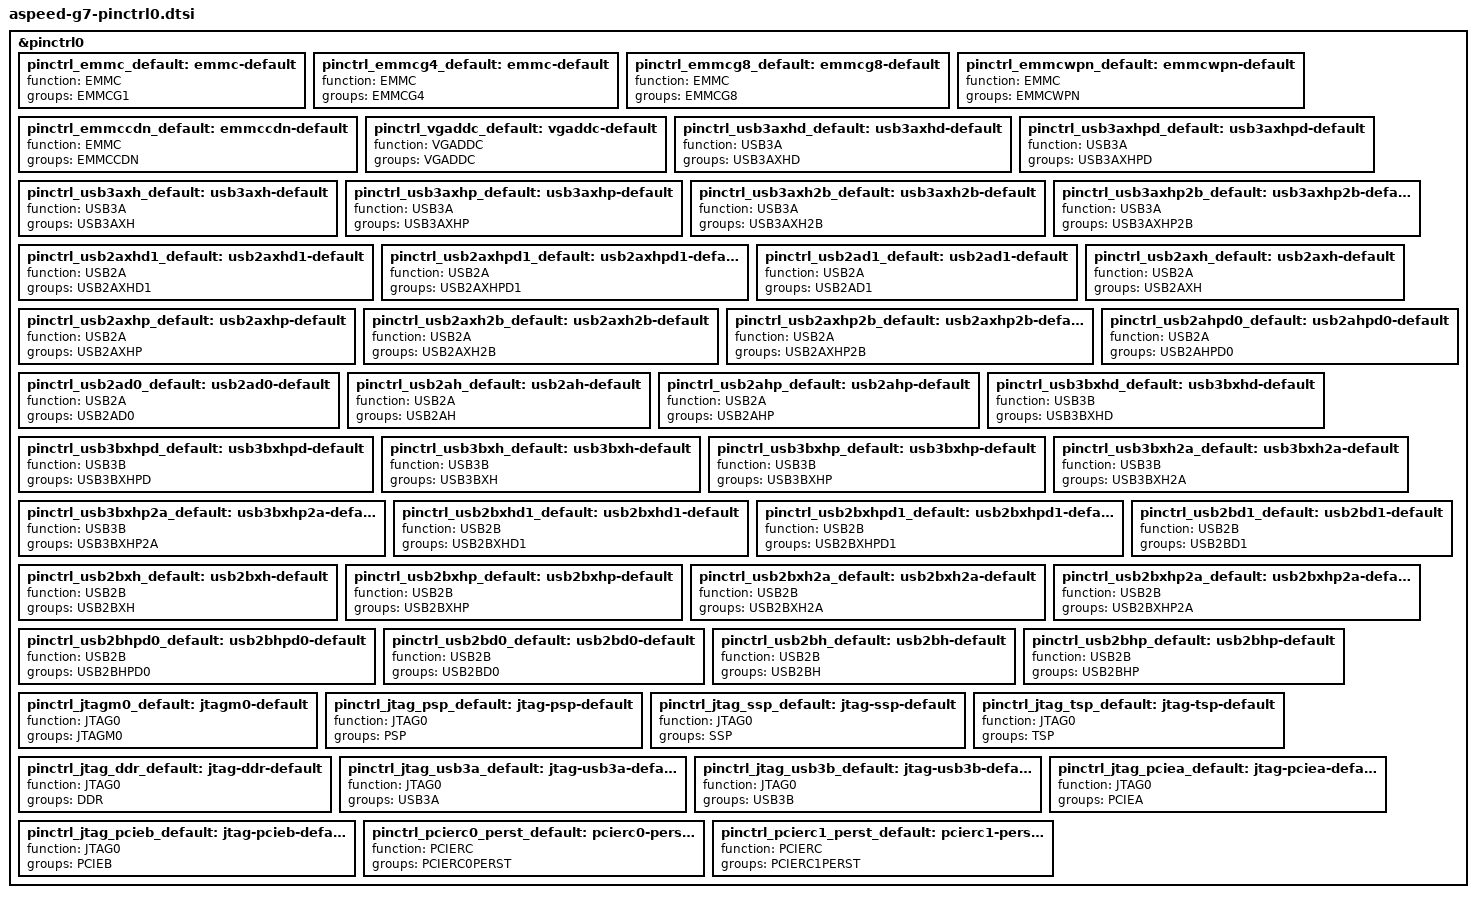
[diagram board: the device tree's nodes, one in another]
// SPDX-License-Identifier: GPL-2.0-or-later
// Copyright 2026 ASPEED Corp.

&pinctrl0 {
	pinctrl_emmc_default: emmc-default {
		function = "EMMC";
		groups = "EMMCG1";
	};

	pinctrl_emmcg4_default: emmc-default {
		function = "EMMC";
		groups = "EMMCG4";
	};

	pinctrl_emmcg8_default: emmcg8-default {
		function = "EMMC";
		groups = "EMMCG8";
	};

	pinctrl_emmcwpn_default: emmcwpn-default {
		function = "EMMC";
		groups = "EMMCWPN";
	};

	pinctrl_emmccdn_default: emmccdn-default {
		function = "EMMC";
		groups = "EMMCCDN";
	};

	pinctrl_vgaddc_default: vgaddc-default {
		function = "VGADDC";
		groups = "VGADDC";
	};

	pinctrl_usb3axhd_default: usb3axhd-default {
		function = "USB3A";
		groups = "USB3AXHD";
	};

	pinctrl_usb3axhpd_default: usb3axhpd-default {
		function = "USB3A";
		groups = "USB3AXHPD";
	};

	pinctrl_usb3axh_default: usb3axh-default {
		function = "USB3A";
		groups = "USB3AXH";
	};

	pinctrl_usb3axhp_default: usb3axhp-default {
		function = "USB3A";
		groups = "USB3AXHP";
	};

	pinctrl_usb3axh2b_default: usb3axh2b-default {
		function = "USB3A";
		groups = "USB3AXH2B";
	};

	pinctrl_usb3axhp2b_default: usb3axhp2b-default {
		function = "USB3A";
		groups = "USB3AXHP2B";
	};

	pinctrl_usb2axhd1_default: usb2axhd1-default {
		function = "USB2A";
		groups = "USB2AXHD1";
	};

	pinctrl_usb2axhpd1_default: usb2axhpd1-default {
		function = "USB2A";
		groups = "USB2AXHPD1";
	};

	pinctrl_usb2ad1_default: usb2ad1-default {
		function = "USB2A";
		groups = "USB2AD1";
	};

	pinctrl_usb2axh_default: usb2axh-default {
		function = "USB2A";
		groups = "USB2AXH";
	};

	pinctrl_usb2axhp_default: usb2axhp-default {
		function = "USB2A";
		groups = "USB2AXHP";
	};

	pinctrl_usb2axh2b_default: usb2axh2b-default {
		function = "USB2A";
		groups = "USB2AXH2B";
	};

	pinctrl_usb2axhp2b_default: usb2axhp2b-default {
		function = "USB2A";
		groups = "USB2AXHP2B";
	};

	pinctrl_usb2ahpd0_default: usb2ahpd0-default {
		function = "USB2A";
		groups = "USB2AHPD0";
	};

	pinctrl_usb2ad0_default: usb2ad0-default {
		function = "USB2A";
		groups = "USB2AD0";
	};

	pinctrl_usb2ah_default: usb2ah-default {
		function = "USB2A";
		groups = "USB2AH";
	};

	pinctrl_usb2ahp_default: usb2ahp-default {
		function = "USB2A";
		groups = "USB2AHP";
	};

	pinctrl_usb3bxhd_default: usb3bxhd-default {
		function = "USB3B";
		groups = "USB3BXHD";
	};

	pinctrl_usb3bxhpd_default: usb3bxhpd-default {
		function = "USB3B";
		groups = "USB3BXHPD";
	};

	pinctrl_usb3bxh_default: usb3bxh-default {
		function = "USB3B";
		groups = "USB3BXH";
	};

	pinctrl_usb3bxhp_default: usb3bxhp-default {
		function = "USB3B";
		groups = "USB3BXHP";
	};

	pinctrl_usb3bxh2a_default: usb3bxh2a-default {
		function = "USB3B";
		groups = "USB3BXH2A";
	};

	pinctrl_usb3bxhp2a_default: usb3bxhp2a-default {
		function = "USB3B";
		groups = "USB3BXHP2A";
	};

	pinctrl_usb2bxhd1_default: usb2bxhd1-default {
		function = "USB2B";
		groups = "USB2BXHD1";
	};

	pinctrl_usb2bxhpd1_default: usb2bxhpd1-default {
		function = "USB2B";
		groups = "USB2BXHPD1";
	};

	pinctrl_usb2bd1_default: usb2bd1-default {
		function = "USB2B";
		groups = "USB2BD1";
	};

	pinctrl_usb2bxh_default: usb2bxh-default {
		function = "USB2B";
		groups = "USB2BXH";
	};

	pinctrl_usb2bxhp_default: usb2bxhp-default {
		function = "USB2B";
		groups = "USB2BXHP";
	};

	pinctrl_usb2bxh2a_default: usb2bxh2a-default {
		function = "USB2B";
		groups = "USB2BXH2A";
	};

	pinctrl_usb2bxhp2a_default: usb2bxhp2a-default {
		function = "USB2B";
		groups = "USB2BXHP2A";
	};

	pinctrl_usb2bhpd0_default: usb2bhpd0-default {
		function = "USB2B";
		groups = "USB2BHPD0";
	};

	pinctrl_usb2bd0_default: usb2bd0-default {
		function = "USB2B";
		groups = "USB2BD0";
	};

	pinctrl_usb2bh_default: usb2bh-default {
		function = "USB2B";
		groups = "USB2BH";
	};

	pinctrl_usb2bhp_default: usb2bhp-default {
		function = "USB2B";
		groups = "USB2BHP";
	};

	pinctrl_jtagm0_default: jtagm0-default {
		function = "JTAG0";
		groups = "JTAGM0";
	};

	pinctrl_jtag_psp_default: jtag-psp-default {
		function = "JTAG0";
		groups = "PSP";
	};

	pinctrl_jtag_ssp_default: jtag-ssp-default {
		function = "JTAG0";
		groups = "SSP";
	};

	pinctrl_jtag_tsp_default: jtag-tsp-default {
		function = "JTAG0";
		groups = "TSP";
	};

	pinctrl_jtag_ddr_default: jtag-ddr-default {
		function = "JTAG0";
		groups = "DDR";
	};

	pinctrl_jtag_usb3a_default: jtag-usb3a-default {
		function = "JTAG0";
		groups = "USB3A";
	};

	pinctrl_jtag_usb3b_default: jtag-usb3b-default {
		function = "JTAG0";
		groups = "USB3B";
	};

	pinctrl_jtag_pciea_default: jtag-pciea-default {
		function = "JTAG0";
		groups = "PCIEA";
	};

	pinctrl_jtag_pcieb_default: jtag-pcieb-default {
		function = "JTAG0";
		groups = "PCIEB";
	};

	pinctrl_pcierc0_perst_default: pcierc0-perst-default {
		function = "PCIERC";
		groups = "PCIERC0PERST";
	};

	pinctrl_pcierc1_perst_default: pcierc1-perst-default {
		function = "PCIERC";
		groups = "PCIERC1PERST";
	};
};
